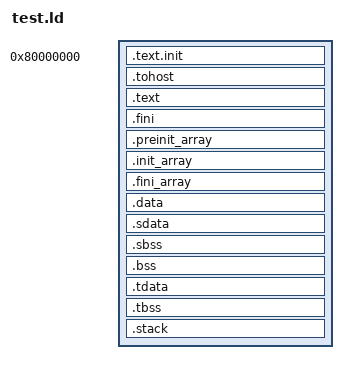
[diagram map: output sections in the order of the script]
/*======================================================================*/
/* Proxy kernel linker script                                           */
/*======================================================================*/
/* This is the linker script used when building the proxy kernel. */

/*----------------------------------------------------------------------*/
/* Setup                                                                */
/*----------------------------------------------------------------------*/

/* The OUTPUT_ARCH command specifies the machine architecture where the
   argument is one of the names used in the BFD library. More
   specifically one of the entires in bfd/cpu-mips.c */

OUTPUT_ARCH( "riscv" )
ENTRY(_start)

/*----------------------------------------------------------------------*/
/* Sections                                                             */
/*----------------------------------------------------------------------*/

SECTIONS
{

  /* text: test code section */
  . = 0x80000000;
  .text.init : { *(.text.init) }

  . = ALIGN(0x1000);
  .tohost : { *(.tohost) }

  .text : { *(.text) }

  .fini :
  {
    KEEP (*(SORT_NONE(.fini)))
  }

  .preinit_array :
  {
    PROVIDE_HIDDEN (__preinit_array_start = .);
    KEEP (*(.preinit_array))
    PROVIDE_HIDDEN (__preinit_array_end = .);
  }

  .init_array :
  {
    PROVIDE_HIDDEN (__init_array_start = .);
    KEEP (*(SORT_BY_INIT_PRIORITY(.init_array.*) SORT_BY_INIT_PRIORITY(.ctors.*)))
    KEEP (*(.init_array EXCLUDE_FILE (*crtbegin.o *crtbegin?.o *crtend.o *crtend?.o ) .ctors))
    PROVIDE_HIDDEN (__init_array_end = .);
  }

  .fini_array :
  {
    PROVIDE_HIDDEN (__fini_array_start = .);
    KEEP (*(SORT_BY_INIT_PRIORITY(.fini_array.*) SORT_BY_INIT_PRIORITY(.dtors.*)))
    KEEP (*(.fini_array EXCLUDE_FILE (*crtbegin.o *crtbegin?.o *crtend.o *crtend?.o ) .dtors))
    PROVIDE_HIDDEN (__fini_array_end = .);
  }

  /* data segment */
  .data : { *(.data) }

  .sdata : {
    __global_pointer$ = . + 0x800;
    *(.srodata.cst16) *(.srodata.cst8) *(.srodata.cst4) *(.srodata.cst2) *(.srodata*)
    *(.sdata .sdata.* .gnu.linkonce.s.*)
  }

  /* bss segment */
  .sbss : {
    *(.sbss .sbss.* .gnu.linkonce.sb.*)
    *(.scommon)
  }
  .bss : { *(.bss) }

  /* thread-local data segment */
  .tdata :
  {
    _tls_data = .;
    *(.tdata.begin)
    *(._tdata_begin)
    *(.tdata)
    *(.tdata.end)
    *(._tdata_end)
  }
  .tbss :
  {
    *(.tbss)
    *(.tbss.end)
    *(._tbss_end)
  }
  _tbss_end = .;

  /* End of uninitalized data segement */
  _end = .;
  end = _end;

  __stack_size = DEFINED(__stack_size) ? __stack_size : 2K;

  .stack (0x80010000 - __stack_size) :
  {
    . = __stack_size;
    PROVIDE( _sp = . );
  }
}

